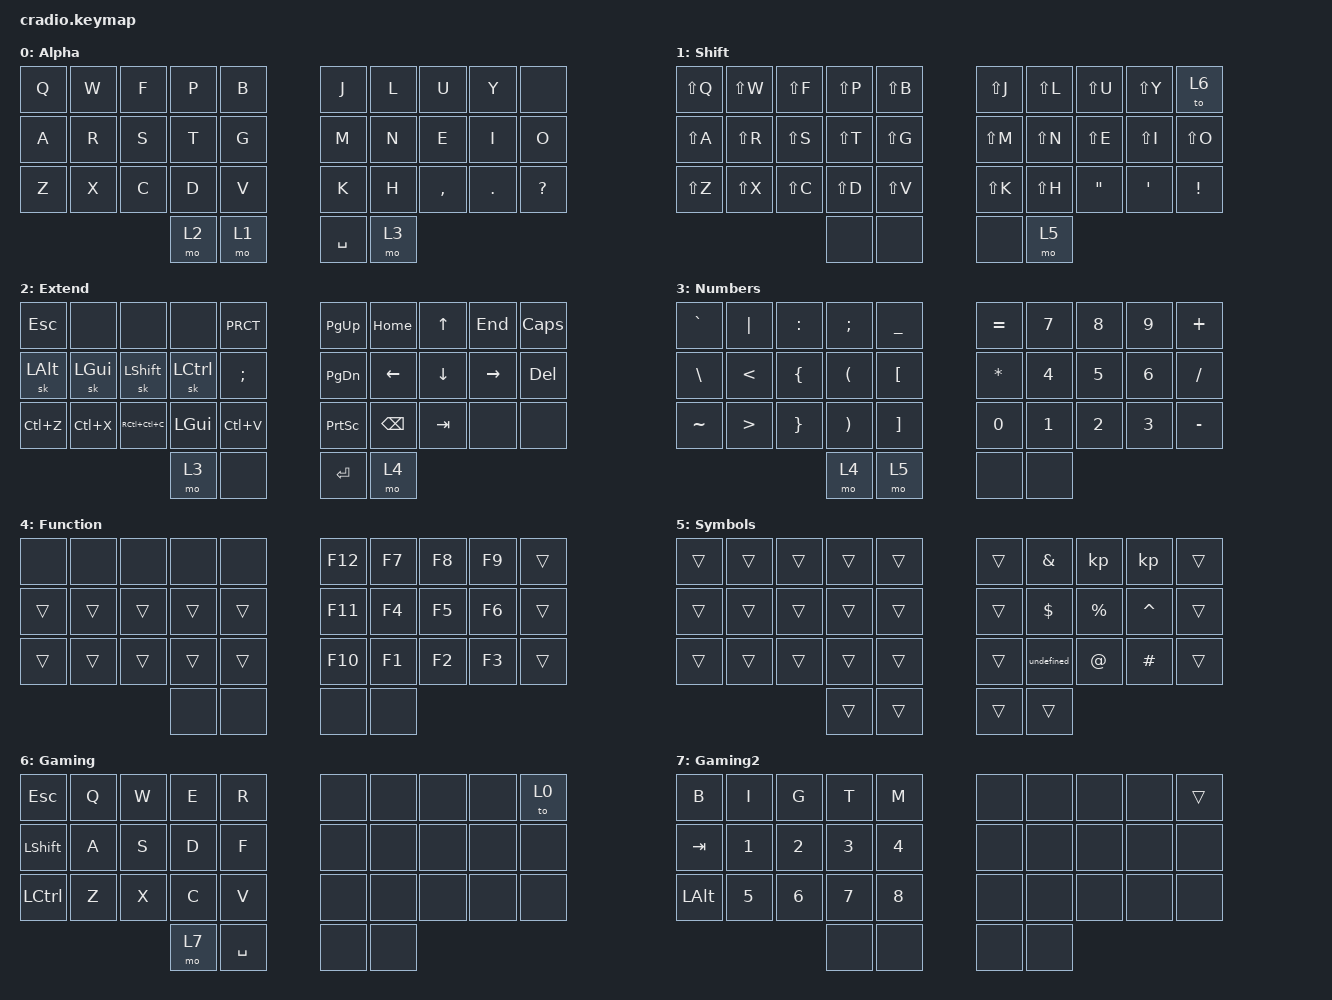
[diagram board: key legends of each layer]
/*
 * Copyright (c) 2020 The ZMK Contributors
 *
 * SPDX-License-Identifier: MIT
 */

#include <behaviors.dtsi>
#include <dt-bindings/zmk/keys.h>

&mt {
    //  flavor = "tap-preferred";
    // tapping_term_ms = <200>;
};

/ {
    combos {
        compatible = "zmk,combos";

        combo_esc {
            timeout-ms = <50>;
            key-positions = <0 1>;
            bindings = <&kp ESC>;
        };

        combo_tab {
            timeout-ms = <50>;
            key-positions = <10 11>;
            bindings = <&kp TAB>;
        };

        combo_ralt {
            timeout-ms = <50>;
            key-positions = <17 16>;
            bindings = <&kp RALT>;
        };

        combo_lalt {
            timeout-ms = <50>;
            key-positions = <11 12>;
            bindings = <&kp LALT>;
        };

        combo_lgui {
            timeout-ms = <50>;
            key-positions = <12 13>;
            bindings = <&kp LGUI>;
        };

        combo_rgui {
            timeout-ms = <50>;
            key-positions = <17 18>;
            bindings = <&kp RGUI>;
        };
    };

    keymap {
        compatible = "zmk,keymap";

        Alpha {
            bindings = <
  &kp Q   &kp W   &kp F   &kp P   &kp B      &kp J   &kp L      &kp U    &kp Y         &none
  &kp A   &kp R   &kp S   &kp T   &kp G      &kp M   &kp N      &kp E    &kp I         &kp O
  &kp Z   &kp X   &kp C   &kp D   &kp V      &kp K   &kp H  &kp COMMA  &kp DOT  &kp QUESTION
                          &mo 2   &mo 1  &kp SPACE   &mo 3
            >;
        };

        Shift {
            bindings = <
 &kp LS(Q)  &kp LS(W)  &kp LS(F)  &kp LS(P)  &kp LS(B)  &kp LS(J)  &kp LS(L)          &kp LS(U)         &kp LS(Y)            &to 6
 &kp LS(A)  &kp LS(R)  &kp LS(S)  &kp LS(T)  &kp LS(G)  &kp LS(M)  &kp LS(N)          &kp LS(E)         &kp LS(I)        &kp LS(O)
 &kp LS(Z)  &kp LS(X)  &kp LS(C)  &kp LS(D)  &kp LS(V)  &kp LS(K)  &kp LS(H)  &kp DOUBLE_QUOTES  &kp SINGLE_QUOTE  &kp EXCLAMATION
                                      &none      &none      &none      &mo 5
            >;
        };

        Extend {
            bindings = <
      &kp ESC         &none           &none         &none   &kp PRCT      &kp PAGE_UP       &kp HOME    &kp UP    &kp END  &kp CAPS
 &sk LEFT_ALT  &sk LEFT_GUI  &sk LEFT_SHIFT     &sk LCTRL   &kp SCLN    &kp PAGE_DOWN       &kp LEFT  &kp DOWN  &kp RIGHT   &kp DEL
    &kp LC(Z)     &kp LC(X)   &kp RC(LC(C))  &kp LEFT_GUI  &kp LC(V)  &kp PRINTSCREEN  &kp BACKSPACE   &kp TAB      &none     &none
                                                    &mo 3      &none        &kp ENTER          &mo 4
            >;
        };

        Numbers {
            bindings = <
     &kp GRAVE          &kp PIPE        &kp COLON          &kp SEMICOLON          &kp UNDER  &kp EQUAL  &kp NUMBER_7  &kp NUMBER_8  &kp NUMBER_9   &kp PLUS
 &kp BACKSLASH     &kp LESS_THAN   &kp LEFT_BRACE   &kp LEFT_PARENTHESIS   &kp LEFT_BRACKET   &kp STAR  &kp NUMBER_4  &kp NUMBER_5  &kp NUMBER_6  &kp SLASH
     &kp TILDE  &kp GREATER_THAN  &kp RIGHT_BRACE  &kp RIGHT_PARENTHESIS  &kp RIGHT_BRACKET     &kp N0  &kp NUMBER_1  &kp NUMBER_2  &kp NUMBER_3  &kp MINUS
                                                                   &mo 4              &mo 5      &none         &none
            >;
        };

        Function {
            bindings = <
  &none   &none   &none   &none   &none  &kp F12  &kp F7  &kp F8  &kp F9  &trans
 &trans  &trans  &trans  &trans  &trans  &kp F11  &kp F4  &kp F5  &kp F6  &trans
 &trans  &trans  &trans  &trans  &trans  &kp F10  &kp F1  &kp F2  &kp F3  &trans
                          &none   &none    &none   &none
            >;
        };

        Symbols {
            bindings = <
 &trans  &trans  &trans  &trans  &trans  &trans  &kp AMPERSAND          &kp        &kp  &trans
 &trans  &trans  &trans  &trans  &trans  &trans     &kp DOLLAR  &kp PERCENT  &kp CARET  &trans
 &trans  &trans  &trans  &trans  &trans  &trans  &kp undefined       &kp AT   &kp HASH  &trans
                         &trans  &trans  &trans         &trans
            >;
        };

        Gaming {
            bindings = <
          &kp ESC   &kp Q   &kp W   &kp E      &kp R   &none   &none   &none   &none   &to 0
   &kp LEFT_SHIFT   &kp A   &kp S   &kp D      &kp F   &none   &none   &none   &none   &none
 &kp LEFT_CONTROL   &kp Z   &kp X   &kp C      &kp V   &none   &none   &none   &none   &none
                                    &mo 7  &kp SPACE   &none   &none
            >;
        };

        Gaming2 {
            bindings = <
        &kp B         &kp I         &kp G         &kp T         &kp M   &none   &none   &none   &none  &trans
      &kp TAB  &kp NUMBER_1  &kp NUMBER_2  &kp NUMBER_3  &kp NUMBER_4   &none   &none   &none   &none   &none
 &kp LEFT_ALT  &kp NUMBER_5  &kp NUMBER_6  &kp NUMBER_7  &kp NUMBER_8   &none   &none   &none   &none   &none
                                                  &none         &none   &none   &none
            >;
        };
    };
};
